# SILABSSYNTH register map
Vendor: SYNTH-Corp; File version: 1.0
Silicon Labs style fixture
CPU: CM33 r0p1, little endian
Registers are 32-bit, access not given, reset 0x0 unless marked. A register's access mark holds for its fields unless they carry their own. Offsets are from the block's base; lines under a group give offsets from that group; [hi:lo] are bit positions; {n}, {i} and the like mark numbered series; 'fields as' and 'values as' point back to an identical list; <NAME> marks a mode.

## Memory map
0x40006000 GPIO size 0x400 — General purpose input output
0x50008000 CMU_S size 0x400 — Clock management unit (secure alias)

## GPIO — General purpose input output
Base 0x40006000
0x00 PA_DOUT
0x30 PD_DOUT
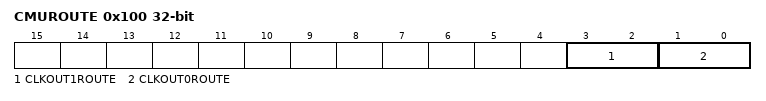
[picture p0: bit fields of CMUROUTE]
0x100 CMUROUTE — CMU clock output routing
  [3:2] CLKOUT1ROUTE, [1:0] CLKOUT0ROUTE

## CMU_S — Clock management unit (secure alias)
Base 0x50008000
0x00 CALCTRL
0x04 CALCNT ro — Calibration result counter
